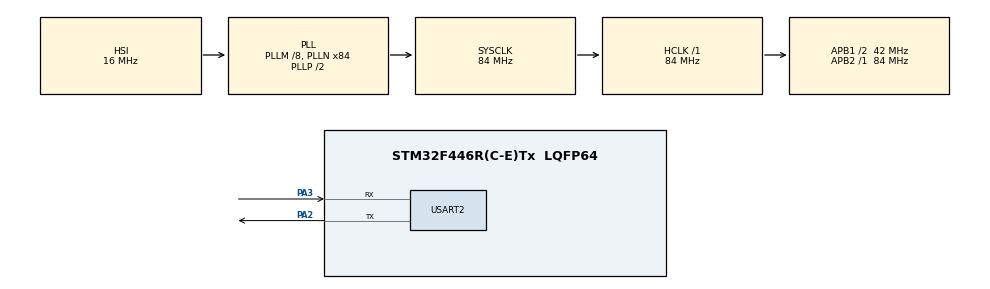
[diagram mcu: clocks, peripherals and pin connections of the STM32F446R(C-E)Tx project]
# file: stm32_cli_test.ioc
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Mcu.Family=STM32F4
Mcu.Name=STM32F446R(C-E)Tx
Mcu.Package=LQFP64
NVIC.PriorityGroup=NVIC_PRIORITYGROUP_4
PA2.Mode=Asynchronous
PA2.Signal=USART2_TX
PA3.Mode=Asynchronous
PA3.Signal=USART2_RX
ProjectManager.HeapSize=0x200
ProjectManager.StackSize=0x400
ProjectManager.TargetToolchain=Makefile
RCC.AHBFreq_Value=84000000
RCC.APB1CLKDivider=RCC_HCLK_DIV2
RCC.APB1Freq_Value=42000000
RCC.APB1TimFreq_Value=84000000
RCC.APB2Freq_Value=84000000
RCC.APB2TimFreq_Value=84000000
RCC.CortexFreq_Value=84000000
RCC.HCLKFreq_Value=84000000
RCC.PLLM=8
RCC.PLLN=84
RCC.SYSCLKFreq_VALUE=84000000
RCC.SYSCLKSource=RCC_SYSCLKSOURCE_PLLCLK
RCC.USBFreq_Value=84000000
RCC.VCOOutputFreq_Value=168000000
USART2.VirtualMode=VM_ASYNC
board=custom

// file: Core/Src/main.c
/* USER CODE BEGIN Header */
/**
  ******************************************************************************
  * @file           : main.c
  * @brief          : Main program body
  ******************************************************************************
  * @attention
  *
  * Copyright (c) 2026 STMicroelectronics.
  * All rights reserved.
  *
  * This software is licensed under terms that can be found in the LICENSE file
  * in the root directory of this software component.
  * If no LICENSE file comes with this software, it is provided AS-IS.
  *
  ******************************************************************************
  */
/* USER CODE END Header */
#include "main.h"
#include "usart.h"
#include "gpio.h"

#include <string.h>
#include <stdio.h>

#include "ring_buffer.h"
#include "logger.h"
#include "temp_sensor.h"
#include "i2c.h"
#include "i2c_driver.h"

void SystemClock_Config(void);

/* USER CODE BEGIN PFP */
void uart_output(const char *str)
{
    HAL_UART_Transmit(&huart2,
                      (uint8_t*)str,
                      strlen(str),
                      HAL_MAX_DELAY);
}
/* USER CODE END PFP */

volatile int done = 0;
uint8_t buf[1];

void on_done(void)
{
    done = 1;
    printf("CALLBACK TRIGGERED\n");
}

int main(void)
{
  HAL_Init();
  SystemClock_Config();

  MX_GPIO_Init();
  MX_USART2_UART_Init();
  // MX_I2C1_Init();

  i2c_init();

  printf("BOOT\n");

  logger_t logger;
  ring_buffer_t rb;

  rb_init(&rb, 10);
  logger_init(&logger, &rb, uart_output);

  printf("scan...\n");

  if (sensor_init() != 0)
  {
      printf("sensor init failed\n");
  }

  while (1)
  {
    done = 0;

    i2c_read_reg_async(0x76 << 1, 0xD0, buf, 1, on_done);

    while (!done);

    printf("chip id = 0x%02X\n", buf[0]);

    HAL_Delay(1000);
  }

  // while (1)
  // {
  //   log_data_t log;
  //   sensor_data_t sensor;

  //   log.timestamp = HAL_GetTick();

  //   // =========================
  //   // 1. read temperature
  //   // =========================
  //   if (sensor_read_temperature(&sensor) != 0)
  //   {
  //       printf("temp read fail\n");
  //       HAL_Delay(1000);
  //       continue;
  //   }

  //   // =========================
  //   // 2. read pressure
  //   // =========================
  //   if (sensor_read_pressure(&sensor) != 0)
  //   {
  //       printf("pressure read fail\n");
  //       HAL_Delay(1000);
  //       continue;
  //   }

  //   log.sensor = sensor;

  //   // =========================
  //   // 3. push to buffer
  //   // =========================
  //   if (rb_push(&rb, log) != 0)
  //   {
  //       printf("rb full\n");
  //   }

  //   // =========================
  //   // 4. print log
  //   // =========================
  //   logger_process(&logger);
  //   HAL_Delay(1000);
  // }
}

void SystemClock_Config(void)
{
  RCC_OscInitTypeDef RCC_OscInitStruct = {0};
  RCC_ClkInitTypeDef RCC_ClkInitStruct = {0};

  /** Configure the main internal regulator output voltage
  */
  __HAL_RCC_PWR_CLK_ENABLE();
  __HAL_PWR_VOLTAGESCALING_CONFIG(PWR_REGULATOR_VOLTAGE_SCALE3);

  /** Initializes the RCC Oscillators according to the specified parameters
  * in the RCC_OscInitTypeDef structure.
  */
  RCC_OscInitStruct.OscillatorType = RCC_OSCILLATORTYPE_HSI;
  RCC_OscInitStruct.HSIState = RCC_HSI_ON;
  RCC_OscInitStruct.HSICalibrationValue = RCC_HSICALIBRATION_DEFAULT;
  RCC_OscInitStruct.PLL.PLLState = RCC_PLL_ON;
  RCC_OscInitStruct.PLL.PLLSource = RCC_PLLSOURCE_HSI;
  RCC_OscInitStruct.PLL.PLLM = 8;
  RCC_OscInitStruct.PLL.PLLN = 84;
  RCC_OscInitStruct.PLL.PLLP = RCC_PLLP_DIV2;
  RCC_OscInitStruct.PLL.PLLQ = 2;
  RCC_OscInitStruct.PLL.PLLR = 2;
  if (HAL_RCC_OscConfig(&RCC_OscInitStruct) != HAL_OK)
  {
    Error_Handler();
  }

  /** Initializes the CPU, AHB and APB buses clocks
  */
  RCC_ClkInitStruct.ClockType = RCC_CLOCKTYPE_HCLK|RCC_CLOCKTYPE_SYSCLK
                              |RCC_CLOCKTYPE_PCLK1|RCC_CLOCKTYPE_PCLK2;
  RCC_ClkInitStruct.SYSCLKSource = RCC_SYSCLKSOURCE_PLLCLK;
  RCC_ClkInitStruct.AHBCLKDivider = RCC_SYSCLK_DIV1;
  RCC_ClkInitStruct.APB1CLKDivider = RCC_HCLK_DIV2;
  RCC_ClkInitStruct.APB2CLKDivider = RCC_HCLK_DIV1;

  if (HAL_RCC_ClockConfig(&RCC_ClkInitStruct, FLASH_LATENCY_2) != HAL_OK)
  {
    Error_Handler();
  }
}

/* USER CODE BEGIN 4 */
int _write(int file, char *ptr, int len)
{
    HAL_UART_Transmit(&huart2, (uint8_t*)ptr, len, HAL_MAX_DELAY);
    return len;
}
/* USER CODE END 4 */

void Error_Handler(void)
{
  __disable_irq();
  while (1)
  {
  }
}
